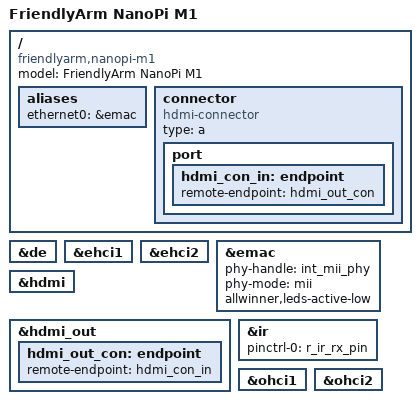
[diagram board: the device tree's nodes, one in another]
#include "sun8i-h3-nanopi.dtsi"
/ {
	model = "FriendlyArm NanoPi M1";
	compatible = "friendlyarm,nanopi-m1", "allwinner,sun8i-h3";
	aliases {
		ethernet0 = &emac;
	};
	connector {
		compatible = "hdmi-connector";
		type = "a";
		port {
			hdmi_con_in: endpoint {
				remote-endpoint = <&hdmi_out_con>;
			};
		};
	};
};
&de {
	status = "okay";
};
&ehci1 {
	status = "okay";
};
&ehci2 {
	status = "okay";
};
&emac {
	phy-handle = <&int_mii_phy>;
	phy-mode = "mii";
	allwinner,leds-active-low;
	status = "okay";
};
&hdmi {
	status = "okay";
};
&hdmi_out {
	hdmi_out_con: endpoint {
		remote-endpoint = <&hdmi_con_in>;
	};
};
&ir {
	pinctrl-names = "default";
	pinctrl-0 = <&r_ir_rx_pin>;
	status = "okay";
};
&ohci1 {
	status = "okay";
};
&ohci2 {
	status = "okay";
};
